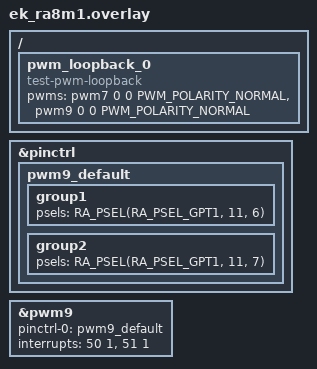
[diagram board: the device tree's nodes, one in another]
/*
 * Copyright (c) 2024 Renesas Electronics Corporation
 * SPDX-License-Identifier: Apache-2.0
 */

#include <zephyr/dt-bindings/pwm/pwm.h>
#include <zephyr/dt-bindings/pwm/ra_pwm.h>

/ {
	pwm_loopback_0 {
		compatible = "test-pwm-loopback";
		/* first index must be a 32-Bit timer */
		pwms = <&pwm7 0 0 PWM_POLARITY_NORMAL>,
			<&pwm9 0 0 PWM_POLARITY_NORMAL>;
	};
};

&pinctrl {
	pwm9_default: pwm9_default {
		group1 {
			/* GTIOC9A */
			psels = <RA_PSEL(RA_PSEL_GPT1, 11, 6)>;
		};
		group2 {
			/* GTIOC9B */
			psels = <RA_PSEL(RA_PSEL_GPT1, 11, 7)>;
		};
	};
};

&pwm9 {
	pinctrl-0 = <&pwm9_default>;
	pinctrl-names = "default";
	interrupts = <50 1>, <51 1>;
	interrupt-names = "gtioca", "overflow";
	status = "okay";
};
